# SRAM_MMR register map
Vendor: Texas Instruments
Peripheral module from a debugger description file (folder CC26x2x7).
Registers are 32-bit, access per field, reset 0x0 unless marked. A register's access mark holds for its fields unless they carry their own. Offsets are as the file gives them; lines under a group give offsets from that group; [hi:lo] are bit positions; {n}, {i} and the like mark numbered series; 'fields as' and 'values as' point back to an identical list; <NAME> marks a mode.

## SRAM_MMR — General Purpose RAM
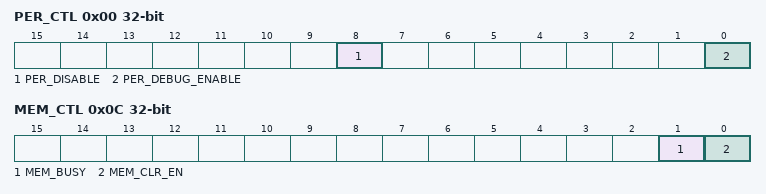
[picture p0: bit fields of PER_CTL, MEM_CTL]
0x00 PER_CTL access not given — Parity Error Control Parity error check controls
  [8] PER_DISABLE rw — Parity Status Disable 0: A parity error will update PER_CHK.PER_ADDR field 1: Parity error does not update PER_CHK.PER_ADDR field
  [0] PER_DEBUG_ENABLE rw — Parity Error Debug Enable 0: Normal operation 1: An address offset can be written to PER_DBG.PER_DEBUG_ADDR and parity errors will be generated on reads from within this offset
0x04 PER_CHK ro — Parity Error Check Parity error check results
  [23:0] PER_ADDR — Parity Error Address Offset Returns the last address offset which resulted in a parity error during an SRAM read. The address offset returned is always the word-aligned address that contains the location with the parity error. For parity faults on non word-aligned accesses, CPU_SCS:BFAR.ADDRESS will hold the address of the location that resulted in parity error.
0x08 PER_DBG — Parity Error Debug Parity error check debug address setting
  [23:0] PER_DEBUG_ADDR rw — Debug Parity Error Address Offset When PER_CTL.PER_DEBUG is 1, this field is used to set a parity debug address offset. The address offset must be a word-aligned address. Writes within this address offset will force incorrect parity bits to be stored together with the data written. The following reads within this same address offset will thus result in parity errors to be generated.
0x0C MEM_CTL — Memory Control Controls memory initialization
  [1] MEM_BUSY ro — Memory Busy status 0: Memory accepts transfers 1: Memory controller is busy during initialization. Read and write transfers are not performed.
  [0] MEM_CLR_EN rw — Memory Contents Initialization enable Writing 1 to MEM_CLR_EN will start memory initialization. The contents of all byte locations will be initialized to 0x00. MEM_BUSY will be 1 until memory initialization has completed.
